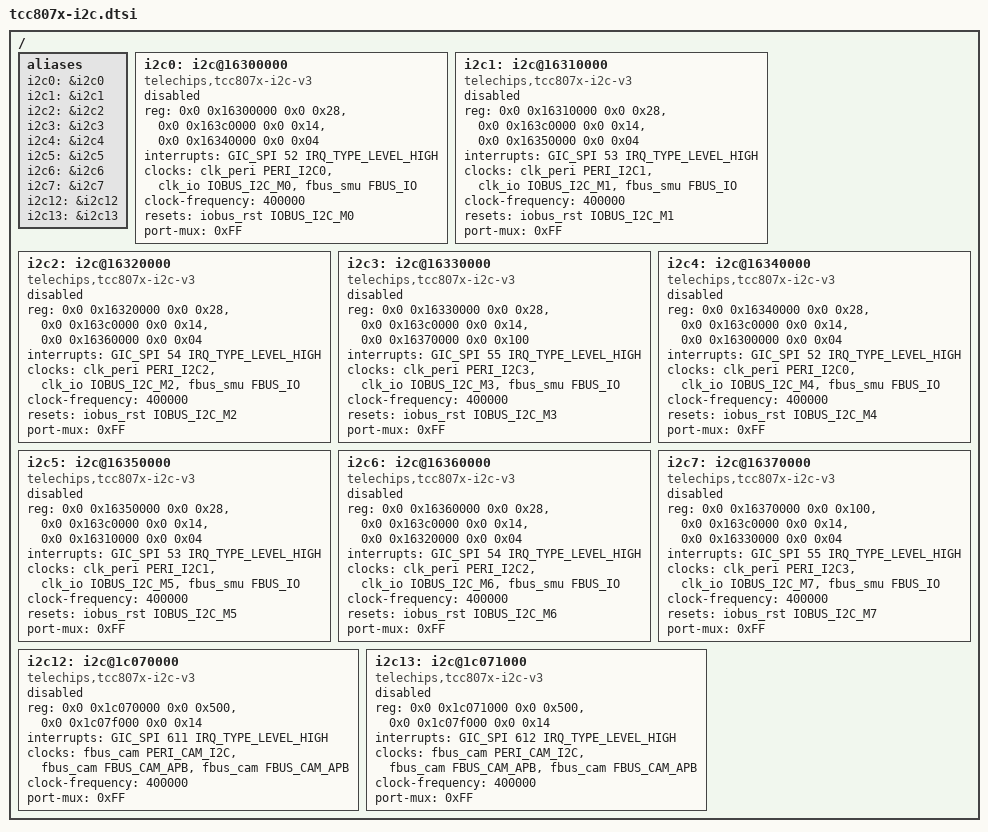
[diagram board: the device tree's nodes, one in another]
// SPDX-License-Identifier: (GPL-2.0-or-later OR MIT)
/*
 * Copyright (C) 2023 Telechips Inc.
 */

#include <dt-bindings/clock/telechips,tcc807x-clks.h>
#include <dt-bindings/interrupt-controller/arm-gic.h>

/ {
	aliases: aliases {
		i2c0 = &i2c0;
		i2c1 = &i2c1;
		i2c2 = &i2c2;
		i2c3 = &i2c3;
		i2c4 = &i2c4;
		i2c5 = &i2c5;
		i2c6 = &i2c6;
		i2c7 = &i2c7;
		i2c12 = &i2c12;
		i2c13 = &i2c13;
	};

	i2c0: i2c@16300000 {
		compatible = "telechips,tcc807x-i2c-v3";
		reg = <0x0 0x16300000 0x0 0x28>,
		      <0x0 0x163c0000 0x0 0x14>,
		      <0x0 0x16340000 0x0 0x04>;
		interrupts = <GIC_SPI 52 IRQ_TYPE_LEVEL_HIGH>;
		#address-cells = <1>;
		#size-cells = <0>;
		clocks = <&clk_peri PERI_I2C0 &clk_io IOBUS_I2C_M0 &fbus_smu FBUS_IO>;
		clock-frequency = <400000>;
		resets = <&iobus_rst IOBUS_I2C_M0>;
		reset-names = "iobus-i2cM0";
		port-mux = <0xFF>;	/* default value */
		status = "disabled";
	};

	i2c1: i2c@16310000 {
		compatible = "telechips,tcc807x-i2c-v3";
		reg = <0x0 0x16310000 0x0 0x28>,
		      <0x0 0x163c0000 0x0 0x14>,
		      <0x0 0x16350000 0x0 0x04>;
		interrupts = <GIC_SPI 53 IRQ_TYPE_LEVEL_HIGH>;
		#address-cells = <1>;
		#size-cells = <0>;
		clocks = <&clk_peri PERI_I2C1 &clk_io IOBUS_I2C_M1 &fbus_smu FBUS_IO>;
		clock-frequency = <400000>;
		resets = <&iobus_rst IOBUS_I2C_M1>;
		reset-names = "iobus-i2cM1";
		port-mux = <0xFF>;	/* default value */
		status = "disabled";
	};

	i2c2: i2c@16320000 {
		compatible = "telechips,tcc807x-i2c-v3";
		reg = <0x0 0x16320000 0x0 0x28>,
		      <0x0 0x163c0000 0x0 0x14>,
		      <0x0 0x16360000 0x0 0x04>;
		interrupts = <GIC_SPI 54 IRQ_TYPE_LEVEL_HIGH>;
		#address-cells = <1>;
		#size-cells = <0>;
		clocks = <&clk_peri PERI_I2C2 &clk_io IOBUS_I2C_M2 &fbus_smu FBUS_IO>;
		clock-frequency = <400000>;
		resets = <&iobus_rst IOBUS_I2C_M2>;
		reset-names = "iobus-i2cM2";
		port-mux = <0xFF>;	/* default value */
		status = "disabled";
	};

	i2c3: i2c@16330000 {
		compatible = "telechips,tcc807x-i2c-v3";
		reg = <0x0 0x16330000 0x0 0x28>,
		      <0x0 0x163c0000 0x0 0x14>,
		      <0x0 0x16370000 0x0 0x100>;
		interrupts = <GIC_SPI 55 IRQ_TYPE_LEVEL_HIGH>;
		#address-cells = <1>;
		#size-cells = <0>;
		clocks = <&clk_peri PERI_I2C3 &clk_io IOBUS_I2C_M3 &fbus_smu FBUS_IO>;
		clock-frequency = <400000>;
		resets = <&iobus_rst IOBUS_I2C_M3>;
		reset-names = "iobus-i2cM3";
		port-mux = <0xFF>;	/* default value */
		status = "disabled";
	};

	i2c4: i2c@16340000 {
		compatible = "telechips,tcc807x-i2c-v3";
		reg = <0x0 0x16340000 0x0 0x28>,
		      <0x0 0x163c0000 0x0 0x14>,
		      <0x0 0x16300000 0x0 0x04>;
		interrupts = <GIC_SPI 52 IRQ_TYPE_LEVEL_HIGH>;
		#address-cells = <1>;
		#size-cells = <0>;
		clocks = <&clk_peri PERI_I2C0 &clk_io IOBUS_I2C_M4 &fbus_smu FBUS_IO>;
		clock-frequency = <400000>;
		resets = <&iobus_rst IOBUS_I2C_M4>;
		reset-names = "iobus-i2cM4";
		port-mux = <0xFF>;	/* default value */
		status = "disabled";
	};

	i2c5: i2c@16350000 {
		compatible = "telechips,tcc807x-i2c-v3";
		reg = <0x0 0x16350000 0x0 0x28>,
		      <0x0 0x163c0000 0x0 0x14>,
		      <0x0 0x16310000 0x0 0x04>;
		interrupts = <GIC_SPI 53 IRQ_TYPE_LEVEL_HIGH>;
		#address-cells = <1>;
		#size-cells = <0>;
		clocks = <&clk_peri PERI_I2C1 &clk_io IOBUS_I2C_M5 &fbus_smu FBUS_IO>;
		clock-frequency = <400000>;
		resets = <&iobus_rst IOBUS_I2C_M5>;
		reset-names = "iobus-i2cM5";
		port-mux = <0xFF>;	/* default value */
		status = "disabled";
	};

	i2c6: i2c@16360000 {
		compatible = "telechips,tcc807x-i2c-v3";
		reg = <0x0 0x16360000 0x0 0x28>,
		      <0x0 0x163c0000 0x0 0x14>,
		      <0x0 0x16320000 0x0 0x04>;
		interrupts = <GIC_SPI 54 IRQ_TYPE_LEVEL_HIGH>;
		#address-cells = <1>;
		#size-cells = <0>;
		clocks = <&clk_peri PERI_I2C2 &clk_io IOBUS_I2C_M6 &fbus_smu FBUS_IO>;
		clock-frequency = <400000>;
		resets = <&iobus_rst IOBUS_I2C_M6>;
		reset-names = "iobus-i2cM6";
		port-mux = <0xFF>;	/* default value */
		status = "disabled";
	};

	i2c7: i2c@16370000 {
		compatible = "telechips,tcc807x-i2c-v3";
		reg = <0x0 0x16370000 0x0 0x100>,
		      <0x0 0x163c0000 0x0 0x14>,
		      <0x0 0x16330000 0x0 0x04>;
		interrupts = <GIC_SPI 55 IRQ_TYPE_LEVEL_HIGH>;
		#address-cells = <1>;
		#size-cells = <0>;
		clocks = <&clk_peri PERI_I2C3 &clk_io IOBUS_I2C_M7 &fbus_smu FBUS_IO>;
		clock-frequency = <400000>;
		resets = <&iobus_rst IOBUS_I2C_M7>;
		reset-names = "iobus-i2cM7";
		port-mux = <0xFF>;	/* default value */
		status = "disabled";
	};
	
	/* camera I2C master 0 */
	i2c12: i2c@1c070000 {
 		compatible = "telechips,tcc807x-i2c-v3";
		reg = <0x0 0x1c070000 0x0 0x500>,
		      <0x0 0x1c07f000 0x0 0x14>;
		interrupts = <GIC_SPI 611 IRQ_TYPE_LEVEL_HIGH>;
 		#address-cells = <1>;
 		#size-cells = <0>;
		clocks = <&fbus_cam PERI_CAM_I2C &fbus_cam FBUS_CAM_APB &fbus_cam FBUS_CAM_APB>;
 		clock-frequency = <400000>;
 		port-mux = <0xFF>;	/* default value */
 		status = "disabled";
	};

	/* camera I2C master 1 */
	i2c13: i2c@1c071000 {
 		compatible = "telechips,tcc807x-i2c-v3";
		reg = <0x0 0x1c071000 0x0 0x500>,
		      <0x0 0x1c07f000 0x0 0x14>;
		interrupts = <GIC_SPI 612 IRQ_TYPE_LEVEL_HIGH>;
 		#address-cells = <1>;
 		#size-cells = <0>;
		clocks = <&fbus_cam PERI_CAM_I2C &fbus_cam FBUS_CAM_APB &fbus_cam FBUS_CAM_APB>;
 		clock-frequency = <400000>;
 		port-mux = <0xFF>;	/* default value */
 		status = "disabled";
	};

};
